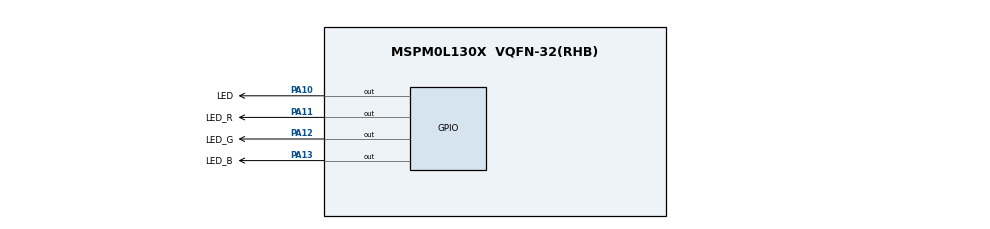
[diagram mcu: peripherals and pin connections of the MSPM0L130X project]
/**
 * @cliArgs --device "MSPM0L130X" --package "VQFN-32(RHB)" --part "Default" --product "mspm0_sdk@1.20.01.06"
 * @versions {"tool":"1.18.0+3266"}
 */

/**
 * Import the modules used in this configuration.
 */
const GPIO   = scripting.addModule("/ti/driverlib/GPIO", {}, false);
const GPIO1  = GPIO.addInstance();
const SYSCTL = scripting.addModule("/ti/driverlib/SYSCTL");

/**
 * Write custom configuration values to the imported modules.
 */
GPIO1.$name                          = "GPIO_LEDS";
GPIO1.port                           = "PORTA";
GPIO1.associatedPins.create(5);
GPIO1.associatedPins[0].$name        = "USER_LED_1";
GPIO1.associatedPins[0].assignedPin  = "0";
GPIO1.associatedPins[1].$name        = "LED";
GPIO1.associatedPins[1].initialValue = "SET";
GPIO1.associatedPins[1].pin.$assign  = "PA10";
GPIO1.associatedPins[2].$name        = "LED_R";
GPIO1.associatedPins[2].initialValue = "SET";
GPIO1.associatedPins[2].pin.$assign  = "PA11";
GPIO1.associatedPins[3].$name        = "LED_G";
GPIO1.associatedPins[3].initialValue = "SET";
GPIO1.associatedPins[3].pin.$assign  = "PA12";
GPIO1.associatedPins[4].$name        = "LED_B";
GPIO1.associatedPins[4].initialValue = "SET";
GPIO1.associatedPins[4].pin.$assign  = "PA13";

const Board = scripting.addModule("/ti/driverlib/Board", {}, false);

SYSCTL.clockTreeEn = true;

/**
 * Pinmux solution for unlocked pins/peripherals. This ensures that minor changes to the automatic solver in a future
 * version of the tool will not impact the pinmux you originally saw.  These lines can be completely deleted in order to
 * re-solve from scratch.
 */
GPIO1.associatedPins[0].pin.$suggestSolution = "PA0";
Board.peripheral.$suggestSolution            = "DEBUGSS";
Board.peripheral.swclkPin.$suggestSolution   = "PA20";
Board.peripheral.swdioPin.$suggestSolution   = "PA19";
